# vcp_cfg register map
Vendor: Texas Instruments
Peripheral module from a debugger description file (folder Keystone2).
Registers are 32-bit, read-write, no defined reset value unless marked. A register's access mark holds for its fields unless they carry their own. Offsets are as the file gives them; lines under a group give offsets from that group; [hi:lo] are bit positions; {n}, {i} and the like mark numbered series; 'fields as' and 'values as' point back to an identical list; <NAME> marks a mode.

## VCP2_7_CFG
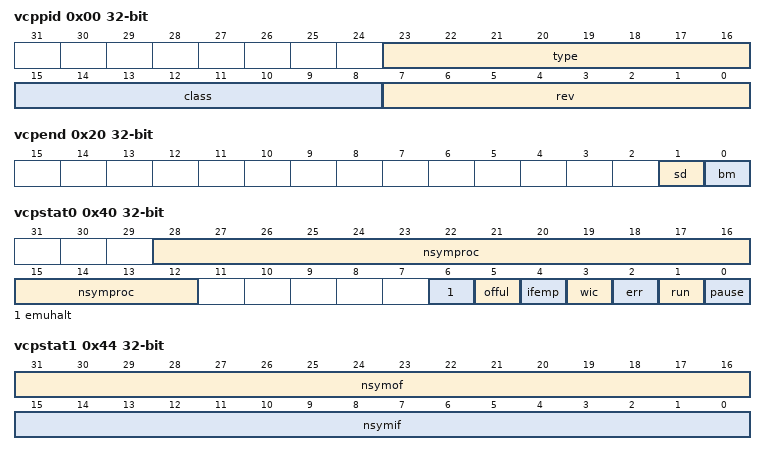
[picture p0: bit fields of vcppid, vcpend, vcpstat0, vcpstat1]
0x00 vcppid
  [23:16] type, [15:8] class, [7:0] rev
0x18 vcpexe
  [3:0] command
0x20 vcpend
  [1] sd, [0] bm
0x40 vcpstat0
  [28:12] nsymproc, [6] emuhalt, [5] offul, [4] ifemp, [3] wic, [2] err, [1] run, [0] pause
0x44 vcpstat1
  [31:16] nsymof, [15:0] nsymif
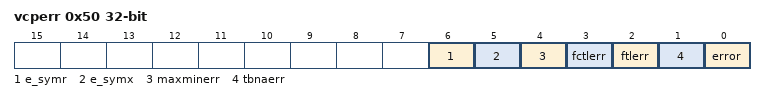
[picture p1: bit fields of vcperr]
0x50 vcperr
  [6] e_symr, [5] e_symx, [4] maxminerr, [3] fctlerr, [2] ftlerr, [1] tbnaerr, [0] error
0x60 vcpemu
  [0] free
